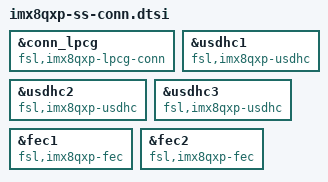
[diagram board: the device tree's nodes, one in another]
// SPDX-License-Identifier: GPL-2.0+
/*
 * Copyright 2018-2020 NXP
 *	Dong Aisheng <aisheng.dong@nxp.com>
 */

&conn_lpcg {
	compatible = "fsl,imx8qxp-lpcg-conn";
};

&usdhc1 {
	compatible = "fsl,imx8qxp-usdhc", "fsl,imx7d-usdhc";
};

&usdhc2 {
	compatible = "fsl,imx8qxp-usdhc", "fsl,imx7d-usdhc";
};

&usdhc3 {
	compatible = "fsl,imx8qxp-usdhc", "fsl,imx7d-usdhc";
};

&fec1 {
	compatible = "fsl,imx8qxp-fec", "fsl,imx6sx-fec";
};

&fec2 {
	compatible = "fsl,imx8qxp-fec", "fsl,imx6sx-fec";
};
